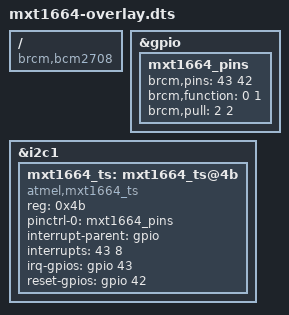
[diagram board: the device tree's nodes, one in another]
// Device tree overlay for I2C connected atmel mxt1664 multiple touch controller
/dts-v1/;
/plugin/;

/ {
	compatible = "brcm,bcm2708";

	fragment@0 {
		target = <&gpio>;
		__overlay__ {
			mxt1664_pins: mxt1664_pins {
				brcm,pins = <43 42>; // interrupt and reset
				brcm,function = <0 1>; // in, out
				brcm,pull = <2 2>; // pull-up, high
			};
		};
	};

	fragment@1 {
		target = <&i2c1>;
		__overlay__ {
			#address-cells = <1>;
			#size-cells = <0>;
			status = "okay";

			mxt1664_ts: mxt1664_ts@4b {
				compatible = "atmel,mxt1664_ts";
				reg = <0x4b>;
				pinctrl-names = "default";
				pinctrl-0 = <&mxt1664_pins>;
				interrupt-parent = <&gpio>;
				interrupts = <43 8>;
				irq-gpios = <&gpio 43 0>;
				reset-gpios = <&gpio 42 0>;
			};
		};
	};

	__overrides__ {
		interrupt = <&mxt1664_pins>,"brcm,pins:0",
			<&mxt1664_ts>,"interrupts:0",
			<&mxt1664_ts>,"irq-gpios:4";
		reset = <&mxt1664_pins>,"brcm,pins:4",
			<&mxt1664_ts>,"reset-gpios:4";
	};
};
